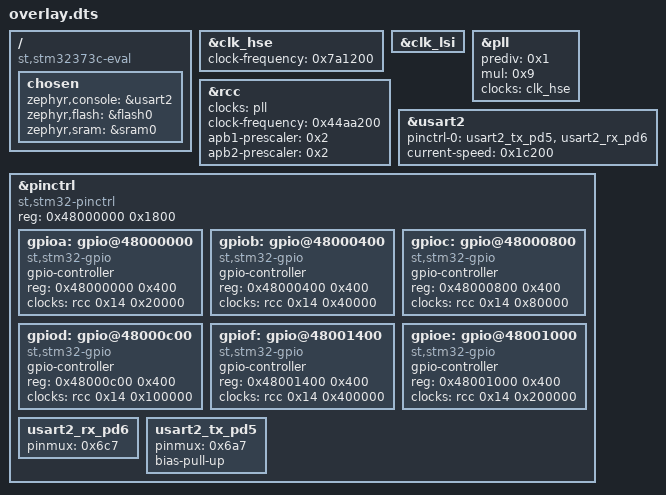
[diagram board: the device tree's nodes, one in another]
/ {
	compatible = "st,stm32373c-eval";
	chosen {
		zephyr,console = &usart2;
		zephyr,flash = &flash0;
		zephyr,sram = &sram0;
	};
};
&clk_hse{
	status = "okay";
	clock-frequency = < 0x7a1200 >;
};
&clk_lsi{
	status = "okay";
};
&pll{
	status = "okay";
	prediv = < 0x1 >;
	mul = < 0x9 >;
	clocks = < &clk_hse >;
};
&rcc{
	clocks = < &pll >;
	clock-frequency = < 0x44aa200 >;
	apb1-prescaler = < 0x2 >;
	apb2-prescaler = < 0x2 >;
};
&usart2{
	status = "okay";
	pinctrl-0 = < &usart2_tx_pd5 &usart2_rx_pd6 >;
	pinctrl-names = "default";
	current-speed = < 0x1c200 >;
};
&pinctrl{
	compatible = "st,stm32-pinctrl";
	#address-cells = < 0x1 >;
	#size-cells = < 0x1 >;
	reg = < 0x48000000 0x1800 >;
	gpioa: gpio@48000000 {
		compatible = "st,stm32-gpio";
		gpio-controller;
		#gpio-cells = < 0x2 >;
		reg = < 0x48000000 0x400 >;
		clocks = < &rcc 0x14 0x20000 >;
	};
	gpiob: gpio@48000400 {
		compatible = "st,stm32-gpio";
		gpio-controller;
		#gpio-cells = < 0x2 >;
		reg = < 0x48000400 0x400 >;
		clocks = < &rcc 0x14 0x40000 >;
	};
	gpioc: gpio@48000800 {
		compatible = "st,stm32-gpio";
		gpio-controller;
		#gpio-cells = < 0x2 >;
		reg = < 0x48000800 0x400 >;
		clocks = < &rcc 0x14 0x80000 >;
	};
	gpiod: gpio@48000c00 {
		compatible = "st,stm32-gpio";
		gpio-controller;
		#gpio-cells = < 0x2 >;
		reg = < 0x48000c00 0x400 >;
		clocks = < &rcc 0x14 0x100000 >;
	};
	gpiof: gpio@48001400 {
		compatible = "st,stm32-gpio";
		gpio-controller;
		#gpio-cells = < 0x2 >;
		reg = < 0x48001400 0x400 >;
		clocks = < &rcc 0x14 0x400000 >;
	};
	gpioe: gpio@48001000 {
		compatible = "st,stm32-gpio";
		gpio-controller;
		#gpio-cells = < 0x2 >;
		reg = < 0x48001000 0x400 >;
		clocks = < &rcc 0x14 0x200000 >;
	};
	usart2_rx_pd6: usart2_rx_pd6 {
		pinmux = < 0x6c7 >;
	};
	usart2_tx_pd5: usart2_tx_pd5 {
		pinmux = < 0x6a7 >;
		bias-pull-up;
	};
};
